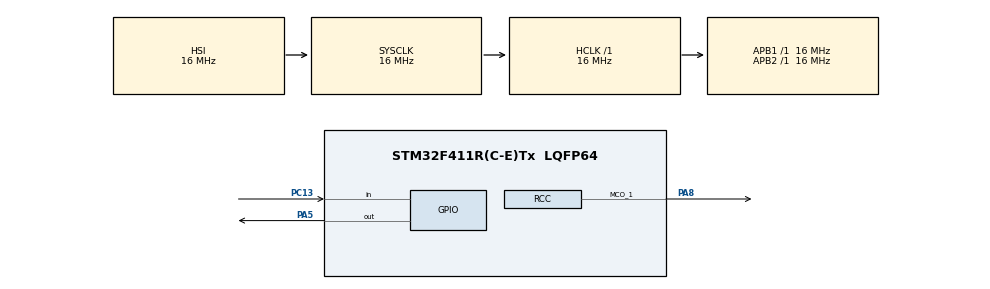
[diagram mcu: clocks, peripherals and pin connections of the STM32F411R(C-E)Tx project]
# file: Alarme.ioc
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Mcu.Family=STM32F4
Mcu.Name=STM32F411R(C-E)Tx
Mcu.Package=LQFP64
NVIC.PriorityGroup=NVIC_PRIORITYGROUP_0
NVIC.RTC_Alarm_IRQn=true\:0\:0\:false\:false\:true\:true\:true\:true
PA5.Signal=GPIO_Output
PA8.Mode=Clock-out-1
PA8.Signal=RCC_MCO_1
PC13-ANTI_TAMP.Signal=GPIO_Input
PC14-OSC32_IN.Mode=LSE-External-Oscillator
PC14-OSC32_IN.Signal=RCC_OSC32_IN
PC15-OSC32_OUT.Mode=LSE-External-Oscillator
PC15-OSC32_OUT.Signal=RCC_OSC32_OUT
ProjectManager.HeapSize=0x200
ProjectManager.StackSize=0x400
ProjectManager.TargetToolchain=STM32CubeIDE
RCC.48MHZClocksFreq_Value=84000000
RCC.AHBFreq_Value=16000000
RCC.APB1Freq_Value=16000000
RCC.APB1TimFreq_Value=16000000
RCC.APB2Freq_Value=16000000
RCC.APB2TimFreq_Value=16000000
RCC.CortexFreq_Value=16000000
RCC.FLatency-AdvancedSettings=FLASH_LATENCY_0
RCC.HCLKFreq_Value=16000000
RCC.HSE_VALUE=8000000
RCC.HSI_VALUE=16000000
RCC.PLLN=336
RCC.PLLP=RCC_PLLP_DIV4
RCC.RCC_MCO1Source=RCC_MCO1SOURCE_LSE
RCC.RCC_RTC_Clock_Source=RCC_RTCCLKSOURCE_LSE
RCC.SYSCLKFreq_VALUE=16000000
RCC.VCOOutputFreq_Value=336000000
RTC.Alarm=RTC_ALARM_A
VP_RTC_VS_RTC_Activate.Mode=RTC_Enabled
VP_RTC_VS_RTC_Alarm_A_Intern.Mode=Alarm A
VP_RTC_VS_RTC_Calendar.Mode=RTC_Calendar
board=NUCLEO-F411RE

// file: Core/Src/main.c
/* USER CODE BEGIN Header */
/**
  ******************************************************************************
  * @file           : main.c
  * @brief          : Main program body
  ******************************************************************************
  * @attention
  *
  * Copyright (c) 2024 STMicroelectronics.
  * All rights reserved.
  *
  * This software is licensed under terms that can be found in the LICENSE file
  * in the root directory of this software component.
  * If no LICENSE file comes with this software, it is provided AS-IS.
  *
  ******************************************************************************
  */
/* USER CODE END Header */
#include "main.h"

RTC_HandleTypeDef hrtc;

/* USER CODE BEGIN PV */
uint8_t segundos, minutos, horas;
uint8_t set_horas;
RTC_TimeTypeDef sTime = {0};
RTC_DateTypeDef sDate = {0};
RTC_AlarmTypeDef sAlarm = {0};
/* USER CODE END PV */

void SystemClock_Config(void);
static void MX_GPIO_Init(void);
static void MX_RTC_Init(void);
/* USER CODE BEGIN PFP */
void relogio() {
	HAL_RTC_GetDate(&hrtc, &sDate, RTC_FORMAT_BIN);
	HAL_RTC_GetTime(&hrtc, &sTime, RTC_FORMAT_BIN);
    segundos = sTime.Seconds;
    HAL_RTC_GetTime(&hrtc, &sTime, RTC_FORMAT_BIN);
    minutos = sTime.Minutes;
	HAL_RTC_GetTime(&hrtc, &sTime, RTC_FORMAT_BIN);
	horas = sTime.Hours;
}
//chamada alarme A
void HAL_RTC_AlarmAEventCallback(RTC_HandleTypeDef *hrtc) {
	HAL_GPIO_TogglePin(GPIOA, GPIO_PIN_5);
}
/* USER CODE END PFP */

int main(void)
{

  /* MCU Configuration--------------------------------------------------------*/

  /* Reset of all peripherals, Initializes the Flash interface and the Systick. */
  HAL_Init();

  /* Configure the system clock */
  SystemClock_Config();

  /* Initialize all configured peripherals */
  MX_GPIO_Init();
  MX_RTC_Init();

  /* Infinite loop */
  while (1)
  {

    /* USER CODE BEGIN 3 */
	  relogio();
	  if(HAL_GPIO_ReadPin(GPIOC, GPIO_PIN_13) == GPIO_PIN_RESET) {
		  MX_RTC_Init(); //reinicia o relógio
	  }
  }
  /* USER CODE END 3 */
}

void SystemClock_Config(void)
{
  RCC_OscInitTypeDef RCC_OscInitStruct = {0};
  RCC_ClkInitTypeDef RCC_ClkInitStruct = {0};

  /** Configure the main internal regulator output voltage
  */
  __HAL_RCC_PWR_CLK_ENABLE();
  __HAL_PWR_VOLTAGESCALING_CONFIG(PWR_REGULATOR_VOLTAGE_SCALE1);

  /** Initializes the RCC Oscillators according to the specified parameters
  * in the RCC_OscInitTypeDef structure.
  */
  RCC_OscInitStruct.OscillatorType = RCC_OSCILLATORTYPE_HSI|RCC_OSCILLATORTYPE_LSE;
  RCC_OscInitStruct.LSEState = RCC_LSE_ON;
  RCC_OscInitStruct.HSIState = RCC_HSI_ON;
  RCC_OscInitStruct.HSICalibrationValue = RCC_HSICALIBRATION_DEFAULT;
  RCC_OscInitStruct.PLL.PLLState = RCC_PLL_NONE;
  if (HAL_RCC_OscConfig(&RCC_OscInitStruct) != HAL_OK)
  {
    Error_Handler();
  }

  /** Initializes the CPU, AHB and APB buses clocks
  */
  RCC_ClkInitStruct.ClockType = RCC_CLOCKTYPE_HCLK|RCC_CLOCKTYPE_SYSCLK
                              |RCC_CLOCKTYPE_PCLK1|RCC_CLOCKTYPE_PCLK2;
  RCC_ClkInitStruct.SYSCLKSource = RCC_SYSCLKSOURCE_HSI;
  RCC_ClkInitStruct.AHBCLKDivider = RCC_SYSCLK_DIV1;
  RCC_ClkInitStruct.APB1CLKDivider = RCC_HCLK_DIV1;
  RCC_ClkInitStruct.APB2CLKDivider = RCC_HCLK_DIV1;

  if (HAL_RCC_ClockConfig(&RCC_ClkInitStruct, FLASH_LATENCY_0) != HAL_OK)
  {
    Error_Handler();
  }
  HAL_RCC_MCOConfig(RCC_MCO1, RCC_MCO1SOURCE_LSE, RCC_MCODIV_1);
}

static void MX_RTC_Init(void)
{

  /** Initialize RTC Only
  */
  hrtc.Instance = RTC;
  hrtc.Init.HourFormat = RTC_HOURFORMAT_24;
  hrtc.Init.AsynchPrediv = 127;
  hrtc.Init.SynchPrediv = 255;
  hrtc.Init.OutPut = RTC_OUTPUT_DISABLE;
  hrtc.Init.OutPutPolarity = RTC_OUTPUT_POLARITY_HIGH;
  hrtc.Init.OutPutType = RTC_OUTPUT_TYPE_OPENDRAIN;
  if (HAL_RTC_Init(&hrtc) != HAL_OK)
  {
    Error_Handler();
  }

  /* USER CODE BEGIN Check_RTC_BKUP */
  if(HAL_GPIO_ReadPin(GPIOC, GPIO_PIN_13) == GPIO_PIN_RESET) {
	  sTime.Hours = sTime.Hours + 1;
	  if(sTime.Hours > 23) {
		  sTime.Hours = 0;
	  }
	  set_horas = 1;
	  //enquanto botao estiver pressionado nao faz nada
	  while(HAL_GPIO_ReadPin(GPIOC, GPIO_PIN_13) == GPIO_PIN_RESET){}
  }
  /* USER CODE END Check_RTC_BKUP */

  /** Initialize RTC and set the Time and Date
  */
  if (set_horas == 0){
	  sTime.Hours = 22;
  }
  sTime.Minutes = 59;
  sTime.Seconds = 55;
  sTime.DayLightSaving = RTC_DAYLIGHTSAVING_NONE;
  sTime.StoreOperation = RTC_STOREOPERATION_RESET;
  if (HAL_RTC_SetTime(&hrtc, &sTime, RTC_FORMAT_BIN) != HAL_OK)
  {
    Error_Handler();
  }
  sDate.WeekDay = RTC_WEEKDAY_MONDAY;
  sDate.Month = RTC_MONTH_JANUARY;
  sDate.Date = 0x1;
  sDate.Year = 0x0;

  if (HAL_RTC_SetDate(&hrtc, &sDate, RTC_FORMAT_BIN) != HAL_OK)
  {
    Error_Handler();
  }

  /** Enable the Alarm A
  */
  sAlarm.AlarmTime.Hours = 5;
  sAlarm.AlarmTime.Minutes = 0;
  sAlarm.AlarmTime.Seconds = 5;
  sAlarm.AlarmTime.SubSeconds = 0;
  sAlarm.AlarmTime.DayLightSaving = RTC_DAYLIGHTSAVING_NONE;
  sAlarm.AlarmTime.StoreOperation = RTC_STOREOPERATION_RESET;
  sAlarm.AlarmMask = RTC_ALARMMASK_NONE;
  sAlarm.AlarmSubSecondMask = RTC_ALARMSUBSECONDMASK_ALL;
  sAlarm.AlarmDateWeekDaySel = RTC_ALARMDATEWEEKDAYSEL_DATE;
  sAlarm.AlarmDateWeekDay = 1;
  sAlarm.Alarm = RTC_ALARM_A;
  if (HAL_RTC_SetAlarm_IT(&hrtc, &sAlarm, RTC_FORMAT_BIN) != HAL_OK)
  {
    Error_Handler();
  }

}

static void MX_GPIO_Init(void)
{
  GPIO_InitTypeDef GPIO_InitStruct = {0};

  /* GPIO Ports Clock Enable */
  __HAL_RCC_GPIOC_CLK_ENABLE();
  __HAL_RCC_GPIOA_CLK_ENABLE();

  /*Configure GPIO pin Output Level */
  HAL_GPIO_WritePin(GPIOA, GPIO_PIN_5, GPIO_PIN_RESET);

  /*Configure GPIO pin : PC13 */
  GPIO_InitStruct.Pin = GPIO_PIN_13;
  GPIO_InitStruct.Mode = GPIO_MODE_INPUT;
  GPIO_InitStruct.Pull = GPIO_NOPULL;
  HAL_GPIO_Init(GPIOC, &GPIO_InitStruct);

  /*Configure GPIO pin : PA5 */
  GPIO_InitStruct.Pin = GPIO_PIN_5;
  GPIO_InitStruct.Mode = GPIO_MODE_OUTPUT_PP;
  GPIO_InitStruct.Pull = GPIO_NOPULL;
  GPIO_InitStruct.Speed = GPIO_SPEED_FREQ_LOW;
  HAL_GPIO_Init(GPIOA, &GPIO_InitStruct);

  /*Configure GPIO pin : PA8 */
  GPIO_InitStruct.Pin = GPIO_PIN_8;
  GPIO_InitStruct.Mode = GPIO_MODE_AF_PP;
  GPIO_InitStruct.Pull = GPIO_NOPULL;
  GPIO_InitStruct.Speed = GPIO_SPEED_FREQ_LOW;
  GPIO_InitStruct.Alternate = GPIO_AF0_MCO;
  HAL_GPIO_Init(GPIOA, &GPIO_InitStruct);

}

void Error_Handler(void)
{
  __disable_irq();
  while (1)
  {
  }
}
